# STM32WBA55xx register map
File version: 1.0
Registers are 32-bit, read-write, reset 0x0 unless marked. A register's access mark holds for its fields unless they carry their own. Offsets are from the block's base; [hi:lo] are bit positions; {n}, {i} and the like mark numbered series; 'fields as' and 'values as' point back to an identical list.

## PKA
Base 0x420C2000
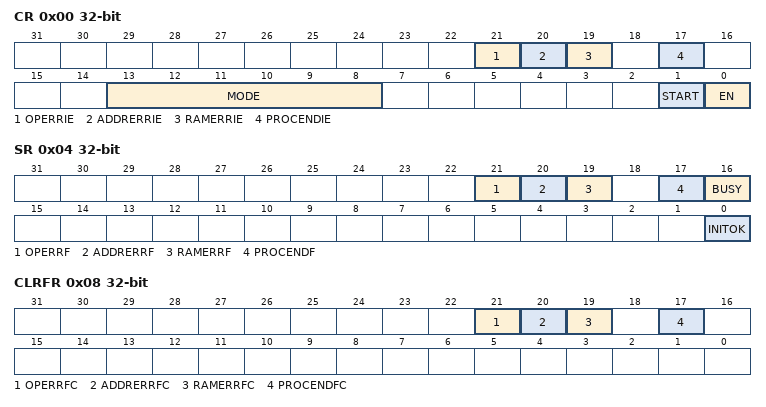
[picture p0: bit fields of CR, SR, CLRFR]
0x00 CR — PKA control register
  [21] OPERRIE — Operation Error interrupt enable
  [20] ADDRERRIE — Address error interrupt enable
  [19] RAMERRIE — RAM error interrupt enable
  [17] PROCENDIE — End of operation interrupt enable
  [13:8] MODE — MODE[5:0] PKA operation code
  [1] START — Start operation
  [0] EN — PKA enable
0x04 SR — PKA status register
  [21] OPERRF — PKA operation Error flag
  [20] ADDRERRF — Address error flag
  [19] RAMERRF — PKA RAM error flag
  [17] PROCENDF — PKA end of operation flag
  [16] BUSY — PKA operation is in progress
  [0] INITOK — PKA initialisation flag
0x08 CLRFR — PKA clear flag register
  [21] OPERRFC — Clear PKA operation Error flag
  [20] ADDRERRFC — Clear address error flag
  [19] RAMERRFC — Clear PKA RAM error flag
  [17] PROCENDFC — Clear PKA end of operation flag
{0x400+4i} RAM[{i}] (i=0..1333)

## SYSCFG — System configuration controller
Base 0x46000400
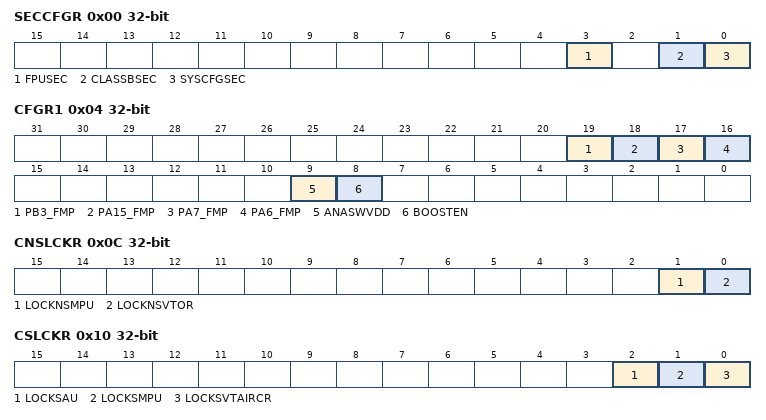
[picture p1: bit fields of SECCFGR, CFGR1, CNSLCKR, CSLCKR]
0x00 SECCFGR — SYSCFG secure configuration register
  [3] FPUSEC — FPU SYSCFG security enable
  [1] CLASSBSEC — ClassB SYSCFG security enable
  [0] SYSCFGSEC — SYSCFG clock control security enable
0x04 CFGR1 — SYSCFG configuration register 1
  [19] PB3_FMP — I2C PB3 Fast mode plus
  [18] PA15_FMP — I2C PA15 Fast mode plus
  [17] PA7_FMP — I2C PA7 Fast mode plus
  [16] PA6_FMP — I2C PA6 Fast mode plus
  [9] ANASWVDD — GPIO analog switch control voltage selection
  [8] BOOSTEN — I/O analog switch voltage booster enable
0x08 FPUIMR — SYSCFG FPU interrupt mask register
  [5:0] FPU_IE — All FPU interrupts enable
0x0C CNSLCKR — SYSCFG CPU non-secure lock register
  [1] LOCKNSMPU — Disable Non-Secure MPU registers writes by SW or debug agent
  [0] LOCKNSVTOR — Disable VTOR_NS register writes by SW or debug agent
0x10 CSLCKR — SYSCFG CPU secure lock register
  [2] LOCKSAU — Disable changes to SAU registers
  [1] LOCKSMPU — Disable changes to the secure MPU registers writes by SW or debug agent
  [0] LOCKSVTAIRCR — Disable changes to the secure vector table address, handling of system faults
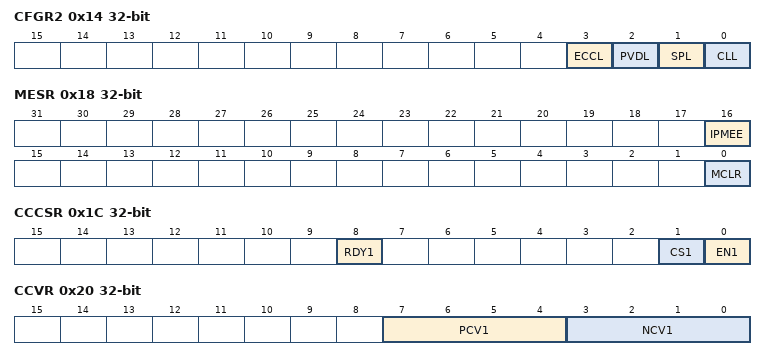
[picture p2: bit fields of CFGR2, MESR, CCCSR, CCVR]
0x14 CFGR2 — SYSCFG configuration register 2
  [3] ECCL — ECC Lock
  [2] PVDL — PVD Lock
  [1] SPL — SRAM Parity Lock
  [0] CLL — Core Lockup Lock
0x18 MESR — SYSCFG Memory Erase Status register
  [16] IPMEE — Status of End of Erase for ICache and PKA RAMs
  [0] MCLR — Status of Erase after Reset
0x1C CCCSR — SYSCFG Conpensation Cell Control&Status register
  [8] RDY1 — VDD compensation cell ready flag
  [1] CS1 — Code selection for VDD power rail
  [0] EN1 — Enable compensation cell for VDD power rail
0x20 CCVR — SYSCFG Conpensation Cell value register
  [7:4] PCV1 — PMOS compensation value for VDD Power Rail
  [3:0] NCV1 — NMOS compensation value for VDD Power Rail
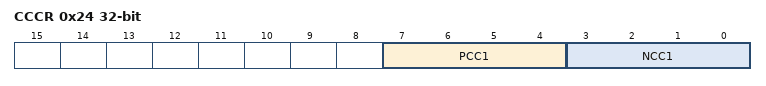
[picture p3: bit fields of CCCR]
0x24 CCCR — SYSCFG Conpensation Cell Code register
  [7:4] PCC1 — PMOS compensation code for VDD Power Rail
  [3:0] NCC1 — NMOS compensation code for VDD Power Rail
0x2C RSSCMDR — SYSCFG RSS command mode register
  [15:0] RSSCMD — RSS command

## COMP12_COMMON
Base 0x46005400
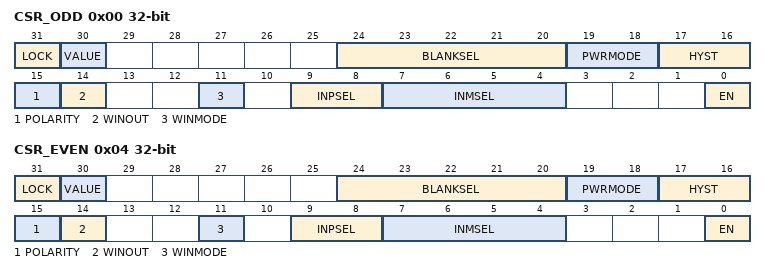
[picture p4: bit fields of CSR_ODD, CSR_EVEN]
0x00 CSR_ODD — COMP control and status register located in register of comparator instance odd, used for bits common to several COMP instances
  [31] LOCK — Comparator lock
  [30] VALUE — Comparator output level
  [24:20] BLANKSEL — Comparator blanking source
    0=NONE (Comparator output without blanking); 1=TIM1_OC5_COMP1 (Comparator output blanking source TIM1 OC5 (specific to COMP instance: COMP1)); 2=TIM2_OC3_COMP1 (Comparator output blanking source TIM2 OC3 (specific to COMP instance: COMP1)); 4=TIM3_OC3_COMP1 (Comparator output blanking source TIM3 OC3 (specific to COMP instance: COMP1))
  [19:18] PWRMODE — Comparator power mode
    0=HIGHSPEED (COMP power mode to high speed); 1=INTERMSPEED (COMP power mode to intermediate speed); 2=MEDIUMSPEED (COMP power mode to medium speed); 3=ULTRALOWPOWER (COMP power mode to ultra-low power)
  [17:16] HYST — Comparator input hysteresis
    0=NONE (No hysteresis); 1=LOW (Hysteresis level low); 2=MEDIUM (Hysteresis level medium); 3=HIGH (Hysteresis level high)
  [15] POLARITY — Comparator output polarity
    0=NONINVERTED (COMP output polarity is not inverted: comparator output is high when the plus (non-inverting) input is at a higher voltage than the minus (inverting) input); 1=INVERTED (COMP output polarity is inverted: comparator output is low when the plus (non-inverting) input is at a lower voltage than the minus (inverting) input)
  [14] WINOUT — Pair of comparators window output level. Bit intended to be used with COMP common instance (COMP_Common_TypeDef)
  [11] WINMODE — Pair of comparators window mode. Bit intended to be used with COMP common instance (COMP_Common_TypeDef)
  [9:8] INPSEL — Comparator input plus selection
  [7:4] INMSEL — Comparator input minus selection
    0=MINUS_1_4VREFINT (Comparator input minus connected to 1/4 VrefInt); 1=MINUS_1_2VREFINT (Comparator input minus connected to 1/2 VrefInt); 2=MINUS_3_4VREFINT (Comparator input minus connected to 3/4 VrefInt); 3=VREFINT (Comparator input minus connected to VrefInt); 6=IO1 (Comparator input minus connected to IO1 (pin PA1 for COMP1, pin PB9 for COMP2))
  [0] EN — Comparator enable
0x04 CSR_EVEN — COMP control and status register located in register of comparator instance even, used for bits common to several COMP instances
  fields as CSR_ODD
